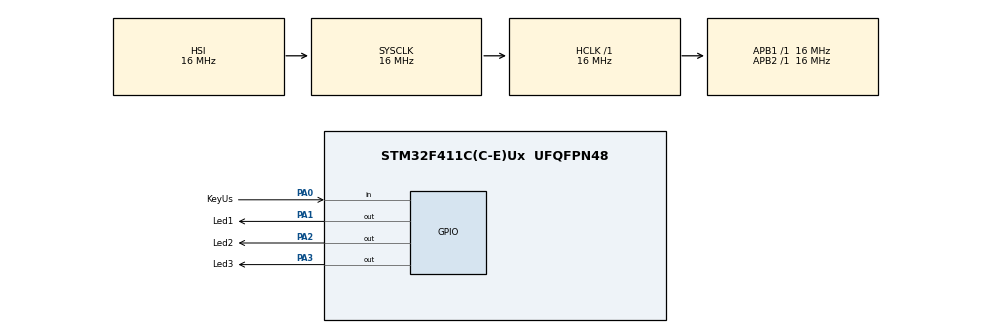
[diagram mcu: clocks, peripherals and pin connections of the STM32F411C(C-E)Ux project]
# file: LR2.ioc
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Mcu.Family=STM32F4
Mcu.Name=STM32F411C(C-E)Ux
Mcu.Package=UFQFPN48
NVIC.PriorityGroup=NVIC_PRIORITYGROUP_4
PA0-WKUP.GPIO_Label=KeyUs
PA0-WKUP.GPIO_PuPd=GPIO_PULLUP
PA0-WKUP.Signal=GPIO_Input
PA1.GPIO_Label=Led1
PA1.Signal=GPIO_Output
PA2.GPIO_Label=Led2
PA2.Signal=GPIO_Output
PA3.GPIO_Label=Led3
PA3.Signal=GPIO_Output
ProjectManager.HeapSize=0x200
ProjectManager.StackSize=0x400
ProjectManager.TargetToolchain=MDK-ARM V5.32
RCC.AHBFreq_Value=16000000
RCC.APB1Freq_Value=16000000
RCC.APB2Freq_Value=16000000
RCC.CortexFreq_Value=16000000
RCC.HSE_VALUE=25000000
RCC.HSI_VALUE=16000000
RCC.LSE_VALUE=32768
RCC.SYSCLKFreq_VALUE=16000000
RCC.VCOOutputFreq_Value=192000000
board=custom

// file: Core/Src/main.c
/* USER CODE BEGIN Header */
/**
  ******************************************************************************
  * @file           : main.c
  * @brief          : Main program body
  ******************************************************************************
  * @attention
  *
  * Copyright (c) 2026 STMicroelectronics.
  * All rights reserved.
  *
  * This software is licensed under terms that can be found in the LICENSE file
  * in the root directory of this software component.
  * If no LICENSE file comes with this software, it is provided AS-IS.
  *
  ******************************************************************************
  */
/* USER CODE END Header */
#include "main.h"

void SystemClock_Config(void);
static void MX_GPIO_Init(void);

int main(void)
{

  /* MCU Configuration--------------------------------------------------------*/

  /* Reset of all peripherals, Initializes the Flash interface and the Systick. */
  HAL_Init();

  /* Configure the system clock */
  SystemClock_Config();

  /* Initialize all configured peripherals */
  MX_GPIO_Init();

  /* Infinite loop */
  while (1)
  {

    /* USER CODE BEGIN 3 */

		// Підключення: 1 GND - [-Індикатор+] - [резистор 325R] - PA1
		//              2 GND - [-Індикатор+] - [резистор 325R] - PA2
	  //              3 GND - [-Key+] - [резистор 330R] - PA0

		/* ФАЗА 1: ІМПУЛЬС (100 мс) */
    HAL_GPIO_WritePin(GPIOA, Led2_Pin, GPIO_PIN_SET); // Вмикаємо Led2 (імпульс)

    // Зчитуємо кнопку. Якщо натиснута (RESET), то вмикаємо Led1
    if(HAL_GPIO_ReadPin(KeyUs_GPIO_Port, KeyUs_Pin) == GPIO_PIN_RESET) {
        HAL_GPIO_WritePin(GPIOA, Led1_Pin, GPIO_PIN_SET);
    } else {
        HAL_GPIO_WritePin(GPIOA, Led1_Pin, GPIO_PIN_RESET);
    }

    HAL_Delay(100); // Тривалість імпульсу

    /* ФАЗА 2: ПАУЗА (400 мс) */
    HAL_GPIO_WritePin(GPIOA, Led2_Pin, GPIO_PIN_RESET); // Вимикаємо Led2

    // Знову перевіряємо кнопку (інвертована логіка)
    if(HAL_GPIO_ReadPin(KeyUs_GPIO_Port, KeyUs_Pin) == GPIO_PIN_RESET) {
        HAL_GPIO_WritePin(GPIOA, Led1_Pin, GPIO_PIN_SET);
    } else {
        HAL_GPIO_WritePin(GPIOA, Led1_Pin, GPIO_PIN_RESET);
    }

    HAL_Delay(400); // Решта періоду до 2 Гц (500мс загалом)

		}
  /* USER CODE END 3 */
}

void SystemClock_Config(void)
{
  RCC_OscInitTypeDef RCC_OscInitStruct = {0};
  RCC_ClkInitTypeDef RCC_ClkInitStruct = {0};

  /** Configure the main internal regulator output voltage
  */
  __HAL_RCC_PWR_CLK_ENABLE();
  __HAL_PWR_VOLTAGESCALING_CONFIG(PWR_REGULATOR_VOLTAGE_SCALE1);

  /** Initializes the RCC Oscillators according to the specified parameters
  * in the RCC_OscInitTypeDef structure.
  */
  RCC_OscInitStruct.OscillatorType = RCC_OSCILLATORTYPE_HSI;
  RCC_OscInitStruct.HSIState = RCC_HSI_ON;
  RCC_OscInitStruct.HSICalibrationValue = RCC_HSICALIBRATION_DEFAULT;
  RCC_OscInitStruct.PLL.PLLState = RCC_PLL_NONE;
  if (HAL_RCC_OscConfig(&RCC_OscInitStruct) != HAL_OK)
  {
    Error_Handler();
  }

  /** Initializes the CPU, AHB and APB buses clocks
  */
  RCC_ClkInitStruct.ClockType = RCC_CLOCKTYPE_HCLK|RCC_CLOCKTYPE_SYSCLK
                              |RCC_CLOCKTYPE_PCLK1|RCC_CLOCKTYPE_PCLK2;
  RCC_ClkInitStruct.SYSCLKSource = RCC_SYSCLKSOURCE_HSI;
  RCC_ClkInitStruct.AHBCLKDivider = RCC_SYSCLK_DIV1;
  RCC_ClkInitStruct.APB1CLKDivider = RCC_HCLK_DIV1;
  RCC_ClkInitStruct.APB2CLKDivider = RCC_HCLK_DIV1;

  if (HAL_RCC_ClockConfig(&RCC_ClkInitStruct, FLASH_LATENCY_0) != HAL_OK)
  {
    Error_Handler();
  }
}

static void MX_GPIO_Init(void)
{
  GPIO_InitTypeDef GPIO_InitStruct = {0};

  /* GPIO Ports Clock Enable */
  __HAL_RCC_GPIOA_CLK_ENABLE();

  /*Configure GPIO pin Output Level */
  HAL_GPIO_WritePin(GPIOA, Led1_Pin|Led2_Pin|Led3_Pin, GPIO_PIN_RESET);

  /*Configure GPIO pin : KeyUs_Pin */
  GPIO_InitStruct.Pin = KeyUs_Pin;
  GPIO_InitStruct.Mode = GPIO_MODE_INPUT;
  GPIO_InitStruct.Pull = GPIO_PULLUP;
  HAL_GPIO_Init(KeyUs_GPIO_Port, &GPIO_InitStruct);

  /*Configure GPIO pins : Led1_Pin Led2_Pin Led3_Pin */
  GPIO_InitStruct.Pin = Led1_Pin|Led2_Pin|Led3_Pin;
  GPIO_InitStruct.Mode = GPIO_MODE_OUTPUT_PP;
  GPIO_InitStruct.Pull = GPIO_NOPULL;
  GPIO_InitStruct.Speed = GPIO_SPEED_FREQ_LOW;
  HAL_GPIO_Init(GPIOA, &GPIO_InitStruct);

}

void Error_Handler(void)
{
  __disable_irq();
  while (1)
  {
  }
}
